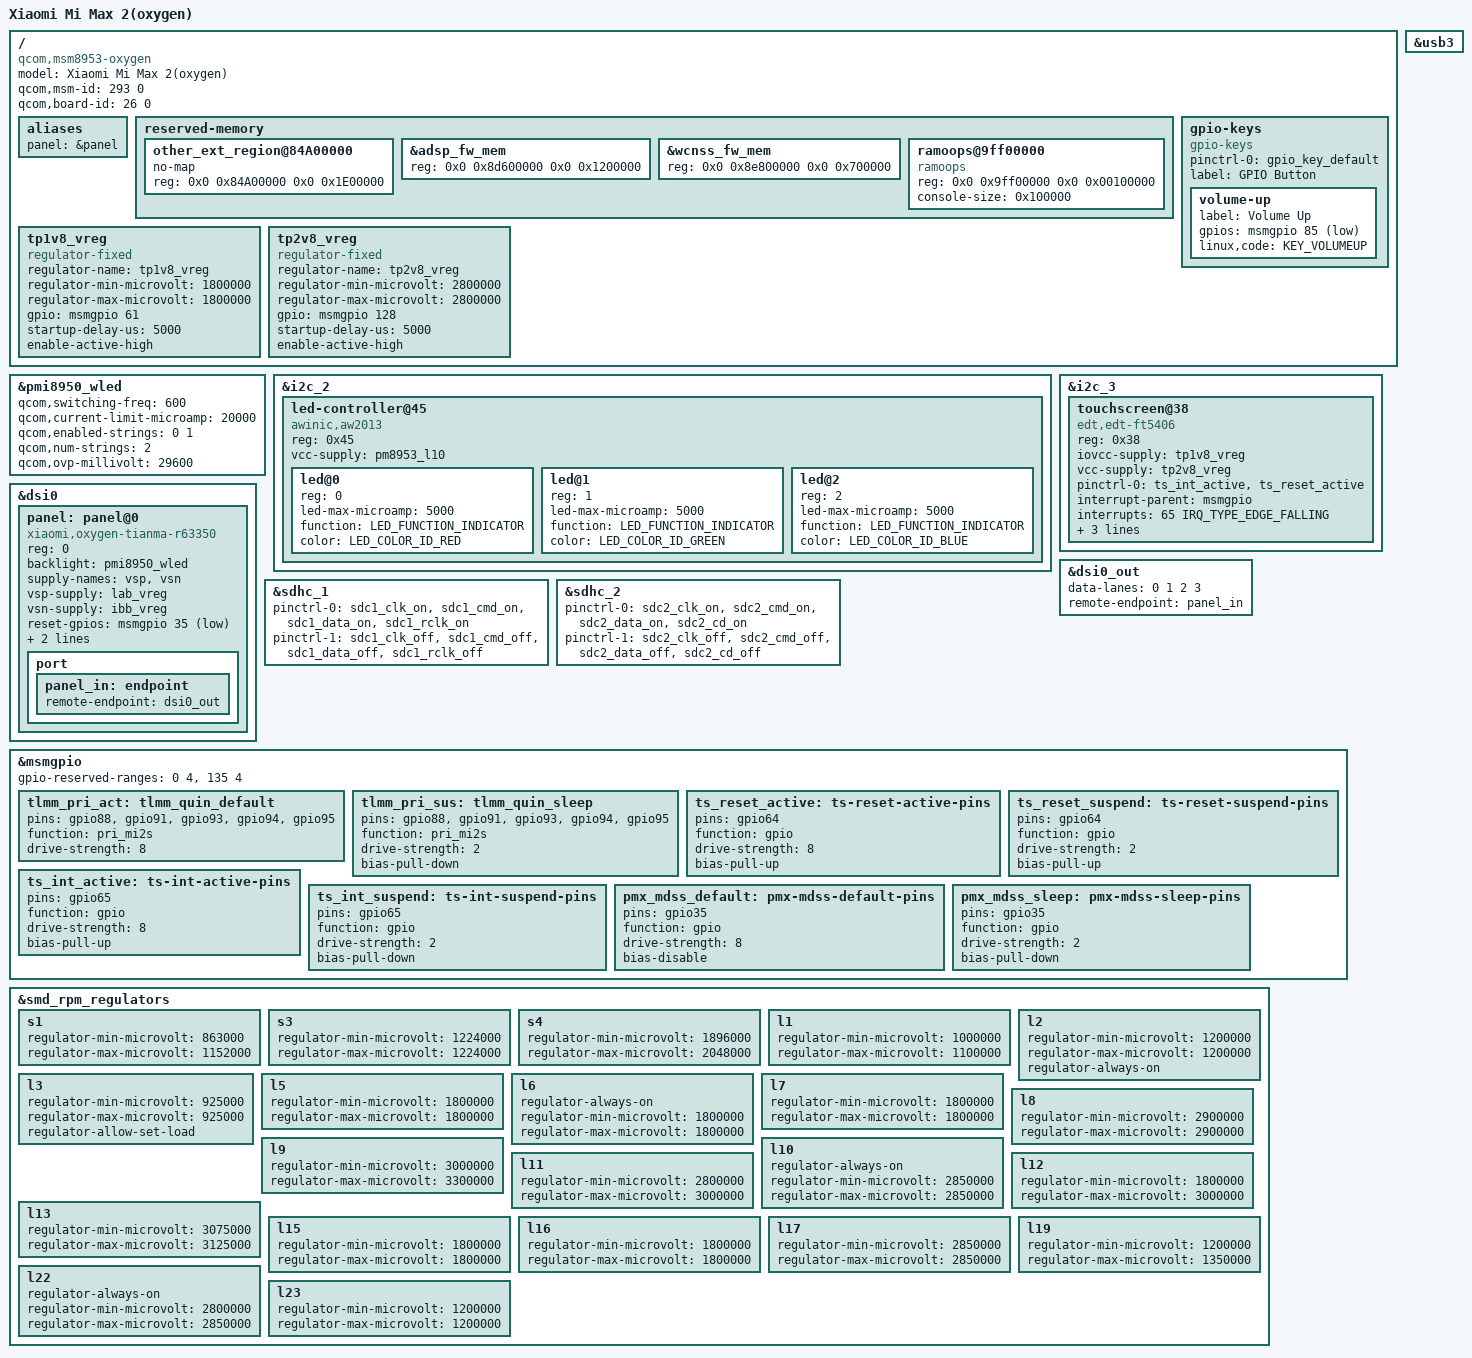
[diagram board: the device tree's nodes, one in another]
/* Copyright (c) 2017,2020 The Linux Foundation. All rights reserved.
 *
 * This program is free software; you can redistribute it and/or modify
 * it under the terms of the GNU General Public License version 2 and
 * only version 2 as published by the Free Software Foundation.
 *
 * This program is distributed in the hope that it will be useful,
 * but WITHOUT ANY WARRANTY; without even the implied warranty of
 * MERCHANTABILITY or FITNESS FOR A PARTICULAR PURPOSE.  See the
 * GNU General Public License for more details.
 */
/dts-v1/;

#include "msm8953-pm8953.dtsi"
#include "pmi8950.dtsi"
#include <dt-bindings/leds/common.h>
#include <dt-bindings/gpio/gpio.h>

/ {
	model = "Xiaomi Mi Max 2(oxygen)";
	compatible = "qcom,msm8953-oxygen", "qcom,msm8953-xiaomi", "qcom,msm8953";

	qcom,msm-id = <293 0>;
	qcom,board-id= <26 0>;

	aliases {
		panel = &panel;
	};

	reserved-memory {
		/delete-node/other_ext_region@85b00000;

		other_ext_region@84A00000 {
			no-map;
			reg = <0x0 0x84A00000 0x0 0x1E00000>;
		};
		
		&adsp_fw_mem {
			reg = <0x0 0x8d600000 0x0 0x1200000>;
		};
		
		&wcnss_fw_mem {
			reg = <0x0 0x8e800000 0x0 0x700000>;
		};

		ramoops@9ff00000 {
			compatible = "ramoops";
			reg = <0x0 0x9ff00000 0x0 0x00100000>;
			console-size = <0x100000>;
		};
	};

	gpio-keys {
		compatible = "gpio-keys";

		pinctrl-names = "default";
		pinctrl-0 = <&gpio_key_default>;

		label = "GPIO Button";

		volume-up {
			label = "Volume Up";
			gpios = <&msmgpio 85 GPIO_ACTIVE_LOW>;
			linux,code = <KEY_VOLUMEUP>;
		};
	};


	tp1v8_vreg: tp1v8_vreg {
		compatible = "regulator-fixed";
		regulator-name = "tp1v8_vreg";
		regulator-min-microvolt = <1800000>;
		regulator-max-microvolt = <1800000>;
		gpio = <&msmgpio 61 0>;
		startup-delay-us = <5000>;
		enable-active-high;
	};

	tp2v8_vreg: tp2v8_vreg {
		compatible = "regulator-fixed";
		regulator-name = "tp2v8_vreg";
		regulator-min-microvolt = <2800000>;
		regulator-max-microvolt = <2800000>;
		gpio = <&msmgpio 128 0>;
		startup-delay-us = <5000>;
		enable-active-high;
	};


};

&pmi8950_wled {
	status = "okay";

	/* Don't copy-paste! See pmi8950.dtsi */
	qcom,switching-freq = <600>;
	qcom,current-limit-microamp = <20000>;
	qcom,enabled-strings = <0 1>;
	qcom,num-strings = <2>;
	qcom,ovp-millivolt = <29600>;
};

&i2c_2 {
	status = "okay";
	/*
	tas2560@4e {
		compatible = "ti,tas2560s";
		reg = <0x4e>;
		};
	*/
	
	led-controller@45 {
		#address-cells = <1>;
		#size-cells = <0>;

		compatible = "awinic,aw2013";

		reg = <0x45>;

		vcc-supply = <&pm8953_l10>;

		led@0 {
			reg = <0>;
			led-max-microamp = <5000>;
			function = LED_FUNCTION_INDICATOR;
			color = <LED_COLOR_ID_RED>;
		};
		led@1 {
			reg = <1>;
			led-max-microamp = <5000>;
			function = LED_FUNCTION_INDICATOR;
			color = <LED_COLOR_ID_GREEN>;
		};
		led@2 {
			reg = <2>;
			led-max-microamp = <5000>;
			function = LED_FUNCTION_INDICATOR;
			color = <LED_COLOR_ID_BLUE>;
		};
	};
};

&i2c_3 {
	status = "okay";

	touchscreen@38 {
		compatible = "edt,edt-ft5406", "edt,edt-ft5x06";
		reg = <0x38>;
		iovcc-supply = <&tp1v8_vreg>;
		vcc-supply = <&tp2v8_vreg>;
		pinctrl-names = "default";
		pinctrl-0 = <&ts_int_active &ts_reset_active>;
		interrupt-parent = <&msmgpio>;
		interrupts = <65 IRQ_TYPE_EDGE_FALLING>;
		reset-gpios = <&msmgpio 64 GPIO_ACTIVE_LOW>;
		touchscreen-size-x = <1080>;
		touchscreen-size-y = <1920>;
	};
};

&dsi0 {
	panel: panel@0 {
		compatible = "xiaomi,oxygen-tianma-r63350";
		reg = <0>;

		backlight = <&pmi8950_wled>;

		supply-names = "vsp", "vsn";
		vsp-supply = <&lab_vreg>;
		vsn-supply = <&ibb_vreg>;

		reset-gpios = <&msmgpio 35 GPIO_ACTIVE_LOW>;

		pinctrl-names = "default", "sleep";
		pinctrl-0 = <&pmx_mdss_default &mdss_te_default>;
		pinctrl-1 = <&pmx_mdss_sleep &mdss_te_default>;

		port {
			panel_in: endpoint {
				remote-endpoint = <&dsi0_out>;
			};
		};
	};
};

&dsi0_out {
	data-lanes = <0 1 2 3>;
	remote-endpoint = <&panel_in>;
};


&sdhc_1 {
	status = "okay";

	pinctrl-names = "default", "sleep";
	pinctrl-0 = <&sdc1_clk_on &sdc1_cmd_on &sdc1_data_on  &sdc1_rclk_on>;
	pinctrl-1 = <&sdc1_clk_off &sdc1_cmd_off &sdc1_data_off &sdc1_rclk_off>;
};

&sdhc_2 {
	status = "okay";

	pinctrl-names = "default", "sleep";
	pinctrl-0 = <&sdc2_clk_on &sdc2_cmd_on &sdc2_data_on &sdc2_cd_on>;
	pinctrl-1 = <&sdc2_clk_off &sdc2_cmd_off &sdc2_data_off &sdc2_cd_off>;

};

&usb3 {
	status = "okay";
};

&msmgpio {

	gpio-reserved-ranges = <0 4>, <135 4>;


	tlmm_pri_act: tlmm_quin_default {
		pins = "gpio88", "gpio91", "gpio93", "gpio94", "gpio95";
		function = "pri_mi2s";
		drive-strength = <8>;
		/* bias-disable; */
	};

	tlmm_pri_sus: tlmm_quin_sleep {
		pins = "gpio88", "gpio91", "gpio93", "gpio94", "gpio95";
		function = "pri_mi2s";
		drive-strength = <2>;
		bias-pull-down;
	};
	
	ts_reset_active: ts-reset-active-pins {
		pins = "gpio64";
		function = "gpio";
		drive-strength = <8>;
		bias-pull-up;
	};

	ts_reset_suspend: ts-reset-suspend-pins {
		pins = "gpio64";
		function = "gpio";
		drive-strength = <2>;
		bias-pull-up;
	};
	ts_int_active: ts-int-active-pins {
		pins = "gpio65";
		function = "gpio";
		drive-strength = <8>;
		bias-pull-up;
	};

	ts_int_suspend: ts-int-suspend-pins {
		pins = "gpio65";
		function = "gpio";
		drive-strength = <2>;
		bias-pull-down;
	};

	pmx_mdss_default: pmx-mdss-default-pins {
		pins = "gpio35";
		function = "gpio";
		drive-strength = <8>;
		bias-disable;
		
	};

	pmx_mdss_sleep: pmx-mdss-sleep-pins {
		pins = "gpio35";
		function = "gpio";
		drive-strength = <2>;
		bias-pull-down;
	};
};

&smd_rpm_regulators {
	s1 {
		regulator-min-microvolt = <863000>;
		regulator-max-microvolt = <1152000>;
	};
	s3 {
		regulator-min-microvolt = <1224000>;
		regulator-max-microvolt = <1224000>;
	};
	s4 {
		regulator-min-microvolt = <1896000>;
		regulator-max-microvolt = <2048000>;
	};
	l1 {
		regulator-min-microvolt = <1000000>;
		regulator-max-microvolt = <1100000>;
	};
	l2 {
		regulator-min-microvolt = <1200000>;
		regulator-max-microvolt = <1200000>;
		regulator-always-on;
	};
	l3 {
		regulator-min-microvolt = <925000>;
		regulator-max-microvolt = <925000>;
		regulator-allow-set-load;
	};
	l5 {
		regulator-min-microvolt = <1800000>;
		regulator-max-microvolt = <1800000>;
	};
	l6 {
		regulator-always-on;
		regulator-min-microvolt = <1800000>;
		regulator-max-microvolt = <1800000>;
	};
	l7 {
		
		regulator-min-microvolt = <1800000>;
		regulator-max-microvolt = <1800000>;
	};
	l8 {
		regulator-min-microvolt = <2900000>;
		regulator-max-microvolt = <2900000>;
	};
	l9 {
		regulator-min-microvolt = <3000000>;
		regulator-max-microvolt = <3300000>;
	};
	l10 {
		regulator-always-on;
		regulator-min-microvolt = <2850000>;
		regulator-max-microvolt = <2850000>;
	};
	l11 {
		regulator-min-microvolt = <2800000>;
		regulator-max-microvolt = <3000000>;
	};
	l12 {
		regulator-min-microvolt = <1800000>;
		regulator-max-microvolt = <3000000>;
	};
	l13 {
		regulator-min-microvolt = <3075000>;
		regulator-max-microvolt = <3125000>;
	};
	l15 {
		regulator-min-microvolt = <1800000>;
		regulator-max-microvolt = <1800000>;
	};
	l16 {
		regulator-min-microvolt = <1800000>;
		regulator-max-microvolt = <1800000>;
	};
	l17 {
		regulator-min-microvolt = <2850000>;
		regulator-max-microvolt = <2850000>;
	};
	l19 {
		regulator-min-microvolt = <1200000>;
		regulator-max-microvolt = <1350000>;
	};
	l22 {
		regulator-always-on;
		regulator-min-microvolt = <2800000>;
		regulator-max-microvolt = <2850000>;
	};
	l23 {
		regulator-min-microvolt = <1200000>;
		regulator-max-microvolt = <1200000>;
	};
};
